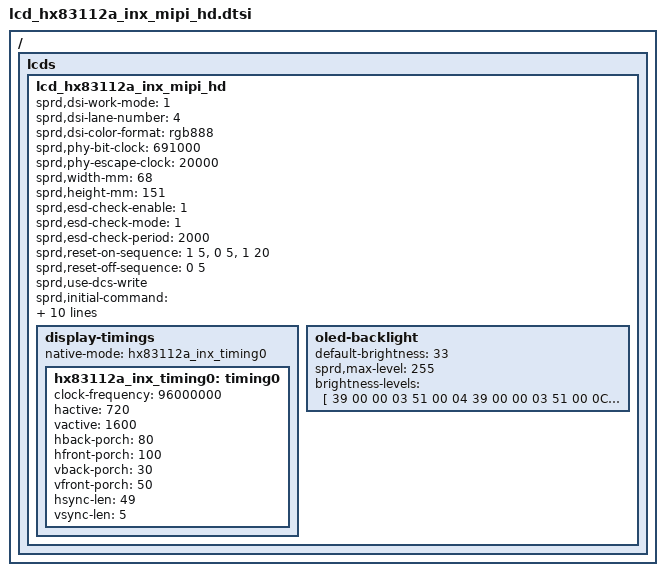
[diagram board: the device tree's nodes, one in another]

/*
 * R61350 Truly LCD config dtsi file for spreadtrum
 *
 * Copyright (C) 2018, Spreadtrum Communications Inc.
 *
 * SPDX-License-Identifier: (GPL-2.0+ OR MIT)
 */

/ {
	fragment {
		target-path = "/";
		__overlay__ {
			lcds {
				lcd_hx83112a_inx_mipi_hd: lcd_hx83112a_inx_mipi_hd {

					sprd,dsi-work-mode = <1>; /* video burst mode*/
					sprd,dsi-lane-number = <4>;
					sprd,dsi-color-format = "rgb888";

					sprd,phy-bit-clock = <691000>;	/* kbps */
					sprd,phy-escape-clock = <20000>;/* kHz */

					sprd,width-mm = <68>;
					sprd,height-mm = <151>;

					sprd,esd-check-enable = <1>;
					sprd,esd-check-mode = <1>;
					sprd,esd-check-period = <2000>;
					/* sprd,esd-check-register = <0x0A>; */
					/* sprd,esd-check-value = <0x9C>; */

					sprd,reset-on-sequence = <1 5>, <0 5>, <1 20>;
					sprd,reset-off-sequence = <0 5>;


					sprd,use-dcs-write;
					sprd,initial-command = [
						39 00 00 04 B9 83 11 2A
						39 00 00 05 CF 00 14 00 C0
						39 00 00 05 C4 06 04 04 81
						39 00 00 02 CC 08
						39 00 00 05 C9 04 0A 8C 01
						39 00 00 09 B1 08 29 29 80 80 4F 4A AA
						39 00 00 10 B2 00 02 00 62 40 00 08 30 14 11 15 00 10 A3 87
						39 00 00 03 D2 2C 2C
						39 00 00 1C B4 0B C8 0B C8 00 00 0B CD 00 00 0B CD 00 FF 00 FF 00 00 0C 0F 00 30 08 0D 0F 00 30
						39 00 00 09 C7 00 00 04 E0 33 00 20 40
						39 00 00 2B D3 C0 00 00 00 00 00 00 05 05 04 04 00 1F 0B 0B 0B 0B 32 10 0A 00 0A 32 16 23 06 23 32 10 06 00 06 00 00 00 00 00 00 00 0A 06 4B
						39 00 00 02 BD 01
						39 00 00 04 CB 25 11 01
						39 00 00 02 BD 00
						39 00 00 31 D5 18 18 18 18 18 18 18 18 18 18 18 18 18 18 18 18 18 18 18 18 31 31 30 30 2F 2F 20 20 00 00 01 01 02 02 03 03 04 04 40 40 19 19 18 18 18 18 18 18
						39 00 00 31 D6 18 18 18 18 18 18 18 18 18 18 18 18 18 18 18 18 18 18 18 18 31 31 30 30 2F 2F 20 20 04 04 03 03 02 02 01 01 00 00 40 40 19 19 18 18 18 18 18 18
						39 00 00 19 D8 AA AA AA AF FE EA AA AA AA AF FE EA AA AA AA AA AA EA AA AA AA AA AA EA
						39 00 00 02 BD 01
						39 00 00 19 D8 AA AA AF EF FF AA AA AA AF EF FF AA AA AA AF EF FF AA AA AA AF EF FF AA
						39 00 00 02 BD 02
						39 00 00 0D D8 AA AA AF EF FF AA AA AA AF EF FF AA
						39 00 00 02 BD 03
						39 00 00 19 D8 AA AA AA AF FE EA AA AA AA AF FE EA AA AA AF FF FF AA AA AA AF FF FF AA
						39 00 00 02 BD 00
						39 00 00 18 E7 0F 0F 1E 72 1E 72 00 50 02 02 00 00 02 02 02 05 14 14 32 B9 23 B9 08
						39 00 00 02 BD 01
						39 00 00 09 E7 02 00 64 01 6E 0E 4B 0F
						39 00 00 02 BD 02
						39 00 00 1E E7 00 00 08 00 01 00 00 00 00 00 00 00 00 00 00 00 00 00 00 00 00 00 04 00 00 00 00 02 00
						39 00 00 02 BD 00
						39 00 00 02 E9 C3
						39 00 00 03 CB D2 28
						39 00 00 02 E9 3F
						39 00 00 02 C1 01
						39 00 00 02 BD 01
						39 00 00 02 E9 C8
						39 00 00 02 D3 81
						39 00 00 02 E9 3F
						39 00 00 02 BD 00
						39 00 00 03 C1 01 00
						39 00 00 02 BD 01
						39 00 00 3A C1 FF F9 F5 F0 EB E6 E1 D8 D3 CF C9 C4 BF BB B6 B0 AC A7 A2 99 90 87 7F 77 6F 67 60 59 51 4A 44 3E 37 30 29 22 1C 16 0F 09 06 05 02 01 00 34 BD 8A D3 18 7A F8 D8 0B 5A 4E 40
						39 00 00 02 BD 02
						39 00 00 3A C1 FF F9 F5 F0 EB E6 E1 D8 D3 CF C9 C4 BF BB B6 B0 AC A7 A2 99 90 87 7F 77 6F 67 60 59 51 4A 44 3E 37 30 29 22 1C 16 0F 09 06 05 02 01 00 34 BD 8A D3 18 7A F8 D8 0B 5A 4E 40
						39 00 00 02 BD 03
						39 00 00 3A C1 FF F9 F5 F0 EB E6 E1 D8 D3 CF C9 C4 BF BB B6 B0 AC A7 A2 99 90 87 7F 77 6F 67 60 59 51 4A 44 3E 37 30 29 22 1C 16 0F 09 06 05 02 01 00 34 BD 8A D3 18 7A F8 D8 0B 5A 4E 40
						39 00 00 02 BD 00
						39 00 00 03 CE 05 10
						39 00 00 3D E6 22 55 22 00 AA 11 22 11 00 AA C0 00 80 C0 6B 33 66 33 00 AA 33 66 33 00 AA 33 66 33 00 AA 33 66 33 00 AA 33 66 33 00 AA 33 66 33 00 AA 33 66 33 00 AA 33 66 33 00 AA 33 66 33 00 AA
						39 00 00 0C E5 06 00 05 05 FE 00 00 00 00 00 00
						05 78 00 01 11
						39 00 00 02 35 00
						39 00 00 03 5E 00 04
						39 00 00 03 51 00 00
						39 00 00 05 C9 04 07 29 01
						39 0A 00 02 55 00
						39 00 00 02 53 24
						05 32 00 01 29
						];

					sprd,sleep-in-command = [
						15 32 00 01 28
						15 96 00 01 10
						];

					sprd,sleep-out-command = [
						15 78 00 01 11
						15 32 00 01 29
						];

					sprd,cabc-off-command = [
					  23 00 00 02 55 00
					  ];
					sprd,cabc-ui-command = [
					  23 00 00 02 55 01
					  ];
					sprd,cabc-still-image-command = [
					  23 00 00 02 55 02
					  ];
					sprd,cabc-video-command = [
					  23 00 00 02 55 03
					  ];

					display-timings {
						native-mode = <&hx83112a_inx_timing0>;

						hx83112a_inx_timing0: timing0 {
							clock-frequency = <96000000>;
							hactive = <720>;
							vactive = <1600>;
							hback-porch = <80>;
							hfront-porch = <100>;
							vback-porch = <30>;
							vfront-porch = <50>;
							hsync-len = <49>;
							vsync-len = <5>;
						};
					};

										oled-backlight {			
						default-brightness = <33>;	
						sprd,max-level = <255>;
						brightness-levels = [				
            		    				39 00 00 03 51 00 04
							39 00 00 03 51 00 0C
							39 00 00 03 51 00 14
							39 00 00 03 51 00 1C
							39 00 00 03 51 00 25
							39 00 00 03 51 00 2D
							39 00 00 03 51 00 35
							39 00 00 03 51 00 3D
							39 00 00 03 51 00 45
							39 00 00 03 51 00 4D
							39 00 00 03 51 00 55
							39 00 00 03 51 00 5D
							39 00 00 03 51 00 65
							39 00 00 03 51 00 6D
							39 00 00 03 51 00 75
							39 00 00 03 51 00 7D
							39 00 00 03 51 00 85
							39 00 00 03 51 00 8D
							39 00 00 03 51 00 95
							39 00 00 03 51 00 9D
							39 00 00 03 51 00 A5
							39 00 00 03 51 00 AD
							39 00 00 03 51 00 B5
							39 00 00 03 51 00 BD
							39 00 00 03 51 00 C5
							39 00 00 03 51 00 CD
							39 00 00 03 51 00 D5
							39 00 00 03 51 00 DD
							39 00 00 03 51 00 E5
							39 00 00 03 51 00 EE
							39 00 00 03 51 00 F6
							39 00 00 03 51 00 FE
							39 00 00 03 51 01 06
							39 00 00 03 51 01 0E
							39 00 00 03 51 01 16
							39 00 00 03 51 01 1E
							39 00 00 03 51 01 26
							39 00 00 03 51 01 2E
							39 00 00 03 51 01 36
							39 00 00 03 51 01 3E
							39 00 00 03 51 01 46
							39 00 00 03 51 01 4E
							39 00 00 03 51 01 56
							39 00 00 03 51 01 5E
							39 00 00 03 51 01 66
							39 00 00 03 51 01 6E
							39 00 00 03 51 01 76
							39 00 00 03 51 01 7E
							39 00 00 03 51 01 86
							39 00 00 03 51 01 8E
							39 00 00 03 51 01 96
							39 00 00 03 51 01 9E
							39 00 00 03 51 01 A6
							39 00 00 03 51 01 AE
							39 00 00 03 51 01 B7
							39 00 00 03 51 01 BF
							39 00 00 03 51 01 C7
							39 00 00 03 51 01 CF
							39 00 00 03 51 01 D7
							39 00 00 03 51 01 DF
							39 00 00 03 51 01 E7
							39 00 00 03 51 01 EF
							39 00 00 03 51 01 F7
							39 00 00 03 51 01 FF
							39 00 00 03 51 02 07
							39 00 00 03 51 02 0F
							39 00 00 03 51 02 17
							39 00 00 03 51 02 1F
							39 00 00 03 51 02 27
							39 00 00 03 51 02 2F
							39 00 00 03 51 02 37
							39 00 00 03 51 02 3F
							39 00 00 03 51 02 47
							39 00 00 03 51 02 4F
							39 00 00 03 51 02 57
							39 00 00 03 51 02 5F
							39 00 00 03 51 02 67
							39 00 00 03 51 02 6F
							39 00 00 03 51 02 77
							39 00 00 03 51 02 80
							39 00 00 03 51 02 88
							39 00 00 03 51 02 90
							39 00 00 03 51 02 98
							39 00 00 03 51 02 A0
							39 00 00 03 51 02 A8
							39 00 00 03 51 02 B0
							39 00 00 03 51 02 B8
							39 00 00 03 51 02 C0
							39 00 00 03 51 02 C8
							39 00 00 03 51 02 D0
							39 00 00 03 51 02 D8
							39 00 00 03 51 02 E0
							39 00 00 03 51 02 E8
							39 00 00 03 51 02 F0
							39 00 00 03 51 02 F8
							39 00 00 03 51 03 00
							39 00 00 03 51 03 08
							39 00 00 03 51 03 10
							39 00 00 03 51 03 18
							39 00 00 03 51 03 20
							39 00 00 03 51 03 28
							39 00 00 03 51 03 30
							39 00 00 03 51 03 38
							39 00 00 03 51 03 40
							39 00 00 03 51 03 49
							39 00 00 03 51 03 51
							39 00 00 03 51 03 59
							39 00 00 03 51 03 61
							39 00 00 03 51 03 69
							39 00 00 03 51 03 71
							39 00 00 03 51 03 79
							39 00 00 03 51 03 81
							39 00 00 03 51 03 89
							39 00 00 03 51 03 91
							39 00 00 03 51 03 99
							39 00 00 03 51 03 A1
							39 00 00 03 51 03 A9
							39 00 00 03 51 03 B1
							39 00 00 03 51 03 B9
							39 00 00 03 51 03 C1
							39 00 00 03 51 03 C9
							39 00 00 03 51 03 D1
							39 00 00 03 51 03 D9
							39 00 00 03 51 03 E1
							39 00 00 03 51 03 E9
							39 00 00 03 51 03 F1
							39 00 00 03 51 03 F9
							39 00 00 03 51 04 01
							39 00 00 03 51 04 09
							39 00 00 03 51 04 12
							39 00 00 03 51 04 1A
							39 00 00 03 51 04 22
							39 00 00 03 51 04 2A
							39 00 00 03 51 04 32
							39 00 00 03 51 04 3A
							39 00 00 03 51 04 42
							39 00 00 03 51 04 4A
							39 00 00 03 51 04 52
							39 00 00 03 51 04 5A
							39 00 00 03 51 04 62
							39 00 00 03 51 04 6A
							39 00 00 03 51 04 72
							39 00 00 03 51 04 7A
							39 00 00 03 51 04 82
							39 00 00 03 51 04 8A
							39 00 00 03 51 04 92
							39 00 00 03 51 04 9A
							39 00 00 03 51 04 A2
							39 00 00 03 51 04 AA
							39 00 00 03 51 04 B2
							39 00 00 03 51 04 BA
							39 00 00 03 51 04 C2
							39 00 00 03 51 04 CA
							39 00 00 03 51 04 D2
							39 00 00 03 51 04 DB
							39 00 00 03 51 04 E3
							39 00 00 03 51 04 EB
							39 00 00 03 51 04 F3
							39 00 00 03 51 04 FB
							39 00 00 03 51 05 03
							39 00 00 03 51 05 0B
							39 00 00 03 51 05 13
							39 00 00 03 51 05 1B
							39 00 00 03 51 05 23
							39 00 00 03 51 05 2B
							39 00 00 03 51 05 33
							39 00 00 03 51 05 3B
							39 00 00 03 51 05 43
							39 00 00 03 51 05 4B
							39 00 00 03 51 05 53
							39 00 00 03 51 05 5B
							39 00 00 03 51 05 63
							39 00 00 03 51 05 6B
							39 00 00 03 51 05 73
							39 00 00 03 51 05 7B
							39 00 00 03 51 05 83
							39 00 00 03 51 05 8B
							39 00 00 03 51 05 93
							39 00 00 03 51 05 9B
							39 00 00 03 51 05 A4
							39 00 00 03 51 05 AC
							39 00 00 03 51 05 B4
							39 00 00 03 51 05 BC
							39 00 00 03 51 05 C4
							39 00 00 03 51 05 CC
							39 00 00 03 51 05 D4
							39 00 00 03 51 05 DC
							39 00 00 03 51 05 E4
							39 00 00 03 51 05 EC
							39 00 00 03 51 05 F4
							39 00 00 03 51 05 FC
							39 00 00 03 51 06 04
							39 00 00 03 51 06 0C
							39 00 00 03 51 06 14
							39 00 00 03 51 06 1C
							39 00 00 03 51 06 24
							39 00 00 03 51 06 2C
							39 00 00 03 51 06 34
							39 00 00 03 51 06 3C
							39 00 00 03 51 06 44
							39 00 00 03 51 06 4C
							39 00 00 03 51 06 54
							39 00 00 03 51 06 5C
							39 00 00 03 51 06 64
							39 00 00 03 51 06 6D
							39 00 00 03 51 06 75
							39 00 00 03 51 06 7D
							39 00 00 03 51 06 85
							39 00 00 03 51 06 8D
							39 00 00 03 51 06 95
							39 00 00 03 51 06 9D
							39 00 00 03 51 06 A5
							39 00 00 03 51 06 AD
							39 00 00 03 51 06 B5
							39 00 00 03 51 06 BD
							39 00 00 03 51 06 C5
							39 00 00 03 51 06 CD
							39 00 00 03 51 06 D5
							39 00 00 03 51 06 DD
							39 00 00 03 51 06 E5
							39 00 00 03 51 06 ED
							39 00 00 03 51 06 F5
							39 00 00 03 51 06 FD
							39 00 00 03 51 07 05
							39 00 00 03 51 07 0D
							39 00 00 03 51 07 15
							39 00 00 03 51 07 1D
							39 00 00 03 51 07 25
							39 00 00 03 51 07 2D
							39 00 00 03 51 07 36
							39 00 00 03 51 07 3E
							39 00 00 03 51 07 46
							39 00 00 03 51 07 4E
							39 00 00 03 51 07 56
							39 00 00 03 51 07 5E
							39 00 00 03 51 07 66
							39 00 00 03 51 07 6E
							39 00 00 03 51 07 76
							39 00 00 03 51 07 7E
							39 00 00 03 51 07 86
							39 00 00 03 51 07 8E
							39 00 00 03 51 07 96
							39 00 00 03 51 07 9E
							39 00 00 03 51 07 A6
							39 00 00 03 51 07 AE
							39 00 00 03 51 07 B6
							39 00 00 03 51 07 BE
							39 00 00 03 51 07 C6
							39 00 00 03 51 07 CE
							39 00 00 03 51 07 D6
							39 00 00 03 51 07 DE
							39 00 00 03 51 07 E6
							39 00 00 03 51 07 EE
							39 00 00 03 51 07 F6
							39 00 00 03 51 07 FF
						];
					};
				};
			};
		};
	};
};
